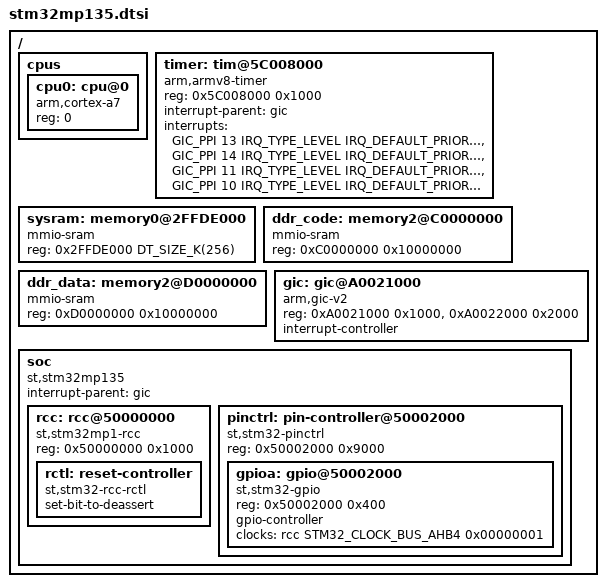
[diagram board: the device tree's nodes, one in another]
/*
 * Copyright (c) 2024 STMicroelectronics
 *
 * SPDX-License-Identifier: Apache-2.0
 */

#include <mem.h>
#include <freq.h>
#include <arm/armv8-r.dtsi>
#include <zephyr/dt-bindings/interrupt-controller/arm-gic.h>
#include <zephyr/dt-bindings/gpio/gpio.h>
#include <zephyr/dt-bindings/clock/stm32_clock.h>

/ {
	cpus {
		#address-cells = <1>;
		#size-cells = <0>;

		cpu0: cpu@0 {
			compatible = "arm,cortex-a7";
			device_type = "cpu";
			reg = <0>;
		};
	};

	timer: tim@5C008000{
		compatible = "arm,armv8-timer";
		reg = <0x5C008000 0x1000>; 
		interrupt-parent = <&gic>;
		interrupts = <GIC_PPI 13 IRQ_TYPE_LEVEL
					IRQ_DEFAULT_PRIORITY>,
					<GIC_PPI 14 IRQ_TYPE_LEVEL
					IRQ_DEFAULT_PRIORITY>,
					<GIC_PPI 11 IRQ_TYPE_LEVEL
					IRQ_DEFAULT_PRIORITY>,
					<GIC_PPI 10 IRQ_TYPE_LEVEL
					IRQ_DEFAULT_PRIORITY>;
	};

	sysram: memory0@2FFDE000  {
		compatible = "mmio-sram";
		reg = <0x2FFDE000 DT_SIZE_K(256)>;
	};


	ddr_code: memory2@C0000000 {
	compatible = "mmio-sram";
	reg = <0xC0000000 0x10000000>;
	};

	ddr_data: memory2@D0000000 {
	compatible = "mmio-sram";
	reg = <0xD0000000 0x10000000>;
	};

	gic: gic@A0021000 {
		compatible = "arm,gic-v2", "arm,gic";
		reg = <0xA0021000 0x1000>,
			  <0xA0022000 0x2000>;
		interrupt-controller;
		#interrupt-cells = <4>;
		status = "okay";
	};

	soc {
		compatible = "st,stm32mp135", "st,stm32mp1", "simple-bus";
		interrupt-parent = <&gic>;

		rcc: rcc@50000000 {
			compatible = "st,stm32mp1-rcc";
			reg = <0x50000000 0x1000>;
			#clock-cells = <2>;

			rctl: reset-controller {
				compatible = "st,stm32-rcc-rctl";
				#reset-cells = <1>;
				set-bit-to-deassert;
			};
		};

		pinctrl: pin-controller@50002000 {
			compatible = "st,stm32-pinctrl";
			reg = <0x50002000 0x9000>;
			#address-cells = <1>;
			#size-cells = <1>;

			gpioa: gpio@50002000 {
				compatible = "st,stm32-gpio";
				reg = <0x50002000 0x400>;
				gpio-controller;
				#gpio-cells = <2>;
				clocks = <&rcc STM32_CLOCK_BUS_AHB4 0x00000001>;
				status = "okay";
			};
		};
	};
};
